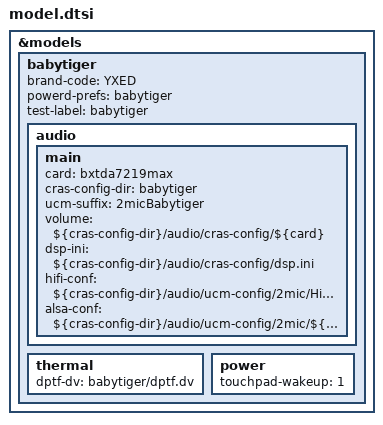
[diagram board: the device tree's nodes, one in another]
/*
 * Copyright 2018 The Chromium OS Authors. All rights reserved.
 *
 * Use of this source code is governed by a BSD-style license that can be
 * found in the LICENSE file.
 */

&models {
	babytiger: babytiger {
		brand-code = "YXED";
		powerd-prefs = "babytiger";
		test-label = "babytiger";
		audio {
			main {
				card = "bxtda7219max";
				cras-config-dir = "babytiger";
				ucm-suffix = "2micBabytiger";
				volume = "${cras-config-dir}/audio/cras-config/${card}";
				dsp-ini = "${cras-config-dir}/audio/cras-config/dsp.ini";
				hifi-conf = "${cras-config-dir}/audio/ucm-config/2mic/HiFi";
				alsa-conf = "${cras-config-dir}/audio/ucm-config/2mic/${card}.conf";
			};
		};
		thermal {
			dptf-dv = "babytiger/dptf.dv";
		};
		power {
			touchpad-wakeup = "1";
		};
	};
};
